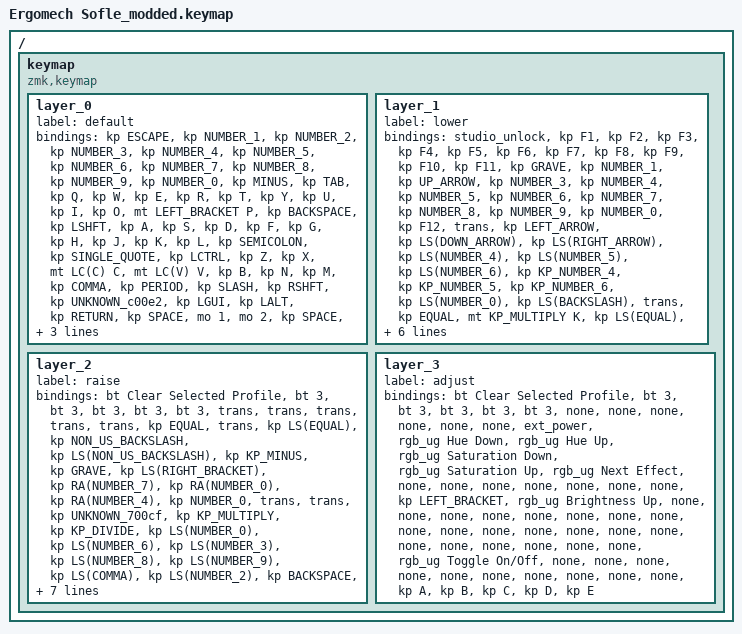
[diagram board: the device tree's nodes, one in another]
// Generated ZMK keymap for Ergomech Sofle
// Keymap: default

#include <behaviors.dtsi>
#include <dt-bindings/zmk/keys.h>
#include <dt-bindings/zmk/studio.h>
#include <dt-bindings/zmk/bt.h>
#include <dt-bindings/zmk/ext_power.h>
#include <dt-bindings/zmk/rgb.h>

// Layer indices
#define L0 0
#define L1 1
#define L2 2
#define L3 3

/ {
    keymap {
        compatible = "zmk,keymap";

        layer_0 {
            label = "default";
            bindings = <
                &kp ESCAPE
                &kp NUMBER_1
                &kp NUMBER_2
                &kp NUMBER_3
                &kp NUMBER_4
                &kp NUMBER_5
                &kp NUMBER_6
                &kp NUMBER_7
                &kp NUMBER_8
                &kp NUMBER_9
                &kp NUMBER_0
                &kp MINUS
                &kp TAB
                &kp Q
                &kp W
                &kp E
                &kp R
                &kp T
                &kp Y
                &kp U
                &kp I
                &kp O
                &mt LEFT_BRACKET P
                &kp BACKSPACE
                &kp LSHFT
                &kp A
                &kp S
                &kp D
                &kp F
                &kp G
                &kp H
                &kp J
                &kp K
                &kp L
                &kp SEMICOLON
                &kp SINGLE_QUOTE
                &kp LCTRL
                &kp Z
                &kp X
                &mt LC(C) C
                &mt LC(V) V
                &kp B
                &kp N
                &kp M
                &kp COMMA
                &kp PERIOD
                &kp SLASH
                &kp RSHFT
                &kp UNKNOWN_c00e2
                &kp LGUI
                &kp LALT
                &kp RETURN
                &kp SPACE
                &mo 1
                &mo 2
                &kp SPACE
                &kp RCTRL
                &kp RALT
                &kp RETURN
                &kp C_PLAY_PAUSE
                &kp RIGHT_ARROW
                &kp UP_ARROW
                &kp LEFT_ARROW
                &kp DOWN_ARROW
            >;
        };

        layer_1 {
            label = "lower";
            bindings = <
                &studio_unlock
                &kp F1
                &kp F2
                &kp F3
                &kp F4
                &kp F5
                &kp F6
                &kp F7
                &kp F8
                &kp F9
                &kp F10
                &kp F11
                &kp GRAVE
                &kp NUMBER_1
                &kp UP_ARROW
                &kp NUMBER_3
                &kp NUMBER_4
                &kp NUMBER_5
                &kp NUMBER_6
                &kp NUMBER_7
                &kp NUMBER_8
                &kp NUMBER_9
                &kp NUMBER_0
                &kp F12
                &trans
                &kp LEFT_ARROW
                &kp LS(DOWN_ARROW)
                &kp LS(RIGHT_ARROW)
                &kp LS(NUMBER_4)
                &kp LS(NUMBER_5)
                &kp LS(NUMBER_6)
                &kp KP_NUMBER_4
                &kp KP_NUMBER_5
                &kp KP_NUMBER_6
                &kp LS(NUMBER_0)
                &kp LS(BACKSLASH)
                &trans
                &kp EQUAL
                &mt KP_MULTIPLY K
                &kp LS(EQUAL)
                &kp LS(LEFT_BRACKET)
                &kp LS(RIGHT_BRACKET)
                &kp LEFT_BRACKET
                &kp KP_NUMBER_1
                &kp KP_NUMBER_2
                &kp KP_NUMBER_3
                &kp BACKSLASH
                &trans
                &trans
                &trans
                &trans
                &trans
                &trans
                &trans
                &trans
                &trans
                &trans
                &trans
                &trans
                &kp A
                &kp B
                &kp C
                &kp D
                &kp E
            >;
        };

        layer_2 {
            label = "raise";
            bindings = <
                &bt Clear Selected Profile
                &bt 3
                &bt 3
                &bt 3
                &bt 3
                &bt 3
                &trans
                &trans
                &trans
                &trans
                &trans
                &kp EQUAL
                &trans
                &kp LS(EQUAL)
                &kp NON_US_BACKSLASH
                &kp LS(NON_US_BACKSLASH)
                &kp KP_MINUS
                &kp GRAVE
                &kp LS(RIGHT_BRACKET)
                &kp RA(NUMBER_7)
                &kp RA(NUMBER_0)
                &kp RA(NUMBER_4)
                &kp NUMBER_0
                &trans
                &trans
                &kp UNKNOWN_700cf
                &kp KP_MULTIPLY
                &kp KP_DIVIDE
                &kp LS(NUMBER_0)
                &kp LS(NUMBER_6)
                &kp LS(NUMBER_3)
                &kp LS(NUMBER_8)
                &kp LS(NUMBER_9)
                &kp LS(COMMA)
                &kp LS(NUMBER_2)
                &kp BACKSPACE
                &trans
                &kp RA(RIGHT_BRACKET)
                &kp KP_PLUS
                &kp RA(NUMBER_8)
                &kp RA(NUMBER_9)
                &kp LS(NUMBER_5)
                &kp RA(NUMBER_2)
                &kp LS(PERIOD)
                &kp COMMA
                &kp PERIOD
                &kp BACKSLASH
                &trans
                &trans
                &trans
                &trans
                &trans
                &trans
                &trans
                &trans
                &trans
                &trans
                &trans
                &trans
                &kp A
                &kp B
                &kp C
                &kp D
                &kp E
            >;
        };

        layer_3 {
            label = "adjust";
            bindings = <
                &bt Clear Selected Profile
                &bt 3
                &bt 3
                &bt 3
                &bt 3
                &bt 3
                &none
                &none
                &none
                &none
                &none
                &none
                &ext_power
                &rgb_ug Hue Down
                &rgb_ug Hue Up
                &rgb_ug Saturation Down
                &rgb_ug Saturation Up
                &rgb_ug Next Effect
                &none
                &none
                &none
                &none
                &none
                &none
                &none
                &kp LEFT_BRACKET
                &rgb_ug Brightness Up
                &none
                &none
                &none
                &none
                &none
                &none
                &none
                &none
                &none
                &none
                &none
                &none
                &none
                &none
                &none
                &none
                &none
                &none
                &none
                &none
                &none
                &rgb_ug Toggle On/Off
                &none
                &none
                &none
                &none
                &none
                &none
                &none
                &none
                &none
                &none
                &kp A
                &kp B
                &kp C
                &kp D
                &kp E
            >;
        };
    };
};
